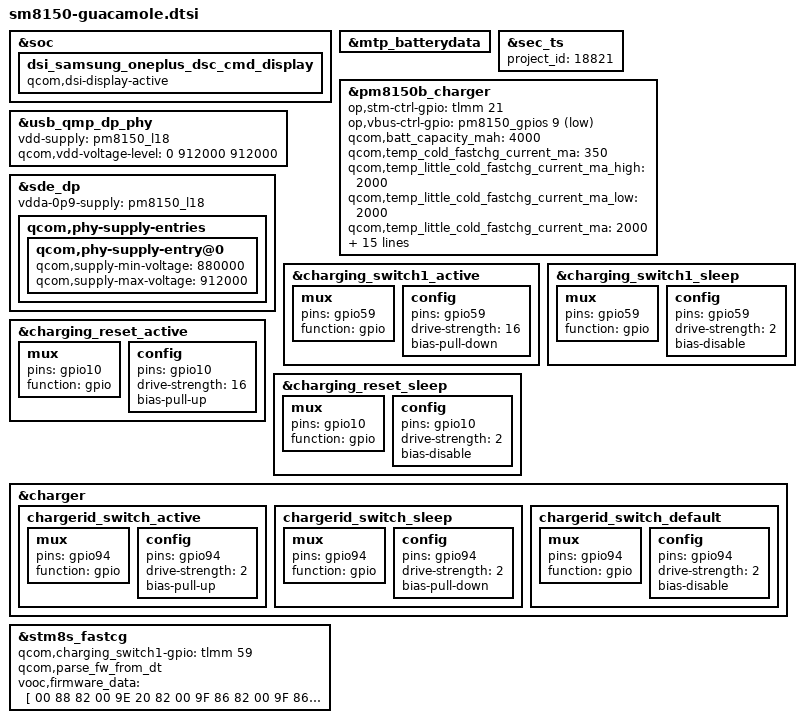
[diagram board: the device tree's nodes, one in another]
/*this is for different project dtsi*/
#include "sm8150-guacamole-common.dtsi"
#include "sm8150-camera-sensor-guacamole.dtsi"

&soc {
	dsi_samsung_oneplus_dsc_cmd_display {
		qcom,dsi-display-active;
	};
};

&mtp_batterydata {
	#include "OP-fg-batterydata-4000mah.dtsi"
};

&sec_ts {
	project_id = <18821>;
};

&pm8150b_charger {
	op,stm-ctrl-gpio = <&tlmm 21 0x00>;
	op,vbus-ctrl-gpio = <&pm8150_gpios 9 GPIO_ACTIVE_LOW>;
};

&usb_qmp_dp_phy {
	vdd-supply = <&pm8150_l18>;
	qcom,vdd-voltage-level = <0 912000 912000>;
};

&sde_dp {
	vdda-0p9-supply = <&pm8150_l18>;
	qcom,phy-supply-entries {
		qcom,phy-supply-entry@0 {
			qcom,supply-min-voltage = <880000>;
			qcom,supply-max-voltage = <912000>;
		};
	};
};

&charging_switch1_active {
	mux {
		pins = "gpio59";
		function = "gpio";
	};

	config {
		pins = "gpio59";
		drive-strength = <16>;
		bias-pull-down;
	};
};

&charging_switch1_sleep {
	mux {
		pins = "gpio59";
		function = "gpio";
	};

	config {
		pins = "gpio59";
		drive-strength = <2>;
		bias-disable;
	};
};

&charging_reset_active {
	mux {
		pins = "gpio10";
		function = "gpio";
	};

	config {
		pins = "gpio10";
		drive-strength = <16>;
		bias-pull-up;
	};
};

&charging_reset_sleep {
	mux {
		pins = "gpio10";
		function = "gpio";
	};

	config {
		pins = "gpio10";
		drive-strength = <2>;
		bias-disable;
	};
};

&charger {
	chargerid_switch_active: chargerid_switch_active {
		mux {
			pins = "gpio94";
			function = "gpio";
		};

		config {
			pins = "gpio94";
			drive-strength = <2>;
			bias-pull-up;
		};
	};

	chargerid_switch_sleep: chargerid_switch_sleep {
		mux {
			pins = "gpio94";
			function = "gpio";
		};

		config {
			pins = "gpio94";
			drive-strength = <2>;
			bias-pull-down;
		};
	};

	chargerid_switch_default: chargerid_switch_default {
		mux {
			pins = "gpio94";
			function = "gpio";
		};

		config {
			pins = "gpio94";
			drive-strength = <2>;
			bias-disable; /* NO PULL */
		};
	};
};

&pm8150b_charger {
	qcom,batt_capacity_mah = <4000>;/*typical capacity*/
	qcom,temp_cold_fastchg_current_ma = <350>;
	qcom,temp_little_cold_fastchg_current_ma_high = <2000>;
	qcom,temp_little_cold_fastchg_current_ma_low = <2000>;
	qcom,temp_little_cold_fastchg_current_ma = <2000>;
	qcom,temp_warm_fastchg_current_ma = <1100>;
	qcom,cold_vfloat_sw_limit = <3700>;
	qcom,cool_vfloat_sw_limit = <4270>;
	/delete-property/ qcom,support_abnormal_adapter;
	qcom,chargerid_switch-gpio = <&tlmm 94 0x00>;
	pinctrl-names = "ship_active", "ship_sleep",
		            "ccdetect_active", "ccdetect_sleep",
		            "dischg_enable", "dischg_disable",
		            "gpio1_adc_default", "gpio12_adc_default",
		            "chargerid_switch_active", "chargerid_switch_sleep", "chargerid_switch_default";
	pinctrl-0 = <&ship_active>;
	pinctrl-1 = <&ship_sleep>;
	pinctrl-2 = <&ccdetect_active>;
	pinctrl-3 = <&ccdetect_sleep>;
	pinctrl-4 = <&dischg_enable>;
	pinctrl-5 = <&dischg_disable>;
	pinctrl-6 = <&gpio1_adc_default>;
	pinctrl-7 = <&gpio12_adc_default>;
	pinctrl-8 = <&chargerid_switch_active>;
	pinctrl-9 = <&chargerid_switch_sleep>;
	pinctrl-10 = <&chargerid_switch_default>;
};

&stm8s_fastcg {
	/delete-property/ qcom,abnormal_adapter_current;
	/delete-property/ qcom,charging_switch1_ctr1-gpio;
	qcom,charging_switch1-gpio = <&tlmm 59 0x00>;
	qcom,parse_fw_from_dt;
	vooc,firmware_data = [
		00 88 82 00 9E 20 82 00 9F 86 82 00 9F 86 82 00 9F 86 82 00 9F 86 82 00 9C A2 82 00 9F 86 82 00 9F 6D 
		20 88 82 00 9F 86 82 00 9F 86 82 00 9F 86 82 00 9F 86 82 00 9F 86 82 00 9F 86 82 00 9F 86 82 00 97 96 
		40 88 82 00 9F 86 82 00 9F 86 82 00 9F 86 82 00 9F 86 82 00 9F 86 82 00 9F 86 82 00 9F 86 82 00 9F 86 
		60 88 82 00 9F 86 82 00 9F 86 82 00 9F 86 82 00 9F 86 82 00 9F 86 82 00 9F 86 82 00 9F 86 82 00 9F 86 
		80 88 C6 00 78 A1 08 24 17 CD 9F 47 B7 00 C6 00 78 5F 97 B6 00 D7 00 57 C6 00 78 4C C7 00 78 81 C6 00 
		A0 88 78 A1 08 27 03 CC 89 A9 CD 9E 67 C6 00 57 A1 01 26 41 C6 00 58 26 3C C6 00 59 A1 01 26 35 C6 00 
		C0 88 5B 48 48 88 C6 00 5A 48 48 48 B7 01 84 BA 01 B7 00 C6 00 5C 48 BA 00 CA 00 5D C7 00 7A 35 09 00 
		E0 88 78 C6 00 43 26 03 CC 89 A9 C6 00 43 4A C7 00 43 CC 89 A9 C6 00 57 26 33 C6 00 58 A1 01 26 2C C6 
		00 89 00 59 A1 01 26 25 C6 00 5B 48 48 88 C6 00 5A 48 48 48 B7 01 84 BA 01 B7 00 C6 00 5C 48 BA 00 CA 
		20 89 00 5D C7 00 7A 35 09 00 78 20 7E C6 00 58 B7 00 A1 01 26 3C C6 00 59 26 37 C6 00 5A A1 01 26 30 
		40 89 C6 00 5C 48 48 88 C6 00 5B 48 48 48 B7 01 84 BA 01 B7 00 C6 00 5D 48 BA 00 CA 00 5E C7 00 7A 35 
		60 89 09 00 78 C6 00 43 27 07 C6 00 43 4A C7 00 43 81 3D 00 26 32 C6 00 59 A1 01 26 2B C6 00 5A A1 01 
		80 89 26 24 C6 00 5C 48 48 88 C6 00 5B 48 48 48 B7 01 84 BA 01 B7 00 C6 00 5D 48 BA 00 CA 00 5E C7 00 
		A0 89 7A 35 09 00 78 81 CD 8F 7E C6 00 79 27 03 CC 8E B9 72 5F 00 49 72 5F 00 4A 72 5F 00 4B 72 5F 00 
		C0 89 4C 72 5F 00 4D 72 5F 00 4E 72 5F 00 4F C6 00 82 A1 02 26 10 C6 00 7A 4E A4 F0 C7 00 83 35 01 00 
		E0 89 4B CC 8E B9 C6 00 82 A1 01 26 10 C6 00 7A CA 00 83 C7 00 83 35 01 00 4B CC 8E B9 C6 00 84 A1 05 
		00 8A 26 2D C6 00 50 C7 00 49 C6 00 51 C7 00 4A C6 00 52 C7 00 4B C6 00 53 C7 00 4C C6 00 54 C7 00 4D 
		20 8A C6 00 55 C7 00 4E C6 00 56 C7 00 4F CC 8E B9 C6 00 84 A1 04 26 12 C6 00 7A 5F 97 CD 9A 62 CF 00 
		40 8A 61 35 01 00 4B CC 8E B9 C6 00 84 A1 03 26 1E C6 00 7A 5F 97 4F 02 90 CE 00 61 BF 00 51 02 BA 00 
		60 8A 01 51 90 CF 00 61 35 01 00 4B CC 8E B9 C6 00 84 A1 02 26 22 C6 00 7A 5F 97 CD 9A 6A 90 CE 00 61 
		80 8A BF 00 51 01 BA 01 01 BA 00 01 51 90 CF 00 61 35 01 00 4B CC 8E B9 C6 00 84 A1 01 26 2D C6 00 7A 
		A0 8A 90 5F 90 97 CE 00 61 90 BF 00 01 BA 01 02 CF 00 61 CD 9F 1C 35 01 00 4B CE 00 3A C3 00 61 27 03 
		C0 8A CC 8E B9 35 01 00 87 CC 8E B9 C6 00 85 27 5D C6 00 85 90 5F 90 97 AE 00 07 BF 00 93 CD 9A 10 1C 
		E0 8A 00 10 90 93 72 A9 FF F9 90 F6 C7 00 49 90 93 72 A9 FF FA 90 F6 C7 00 4A 90 93 72 A9 FF FB 90 F6 
		00 8B C7 00 4B 90 93 72 A9 FF FC 90 F6 C7 00 4C 90 93 72 A9 FF FD 90 F6 C7 00 4D 90 93 72 A9 FF FE 90 
		20 8B F6 C7 00 4E 5A F6 C7 00 4F CC 8E B9 C6 00 7A A1 09 26 11 72 5F 00 82 72 5F 00 84 4F CD 9E 89 35 
		40 8B 01 00 77 81 72 5F 00 82 72 5F 00 84 C6 00 7A 27 2B 4A 27 2B 4A 26 03 CC 8D 55 4A 26 03 CC 8D 9B 
		60 8B 4A 26 03 CC 8E 32 4A 26 03 CC 8E 7B A0 07 26 03 CC 8E 89 4A 26 03 CC 8E A9 CC 8E B9 CC 8F 7E C6 
		80 8B 00 43 27 03 CC 8C AA C6 00 45 A1 01 27 03 CD 8F 7E C6 00 76 C7 00 49 C6 00 98 27 24 C6 00 9C 26 
		A0 8B 1F 35 01 00 4A 35 01 00 4B 35 01 00 4C 72 5F 00 4D 35 01 00 4E 72 5F 00 4F 35 01 00 9C CC 8E B9 
		C0 8B CE 00 5F A3 0D 40 2E 03 CC 8C 98 CE 00 5F 1C F2 C0 90 AE 00 10 CD 9A 2E A3 00 3E 2F 03 AE 00 3D 
		E0 8B C6 00 97 27 13 C6 00 9D 26 0E A3 00 3A 2E 09 AE 00 3A 35 01 00 9D 20 16 C6 00 96 27 11 C6 00 9E 
		00 8C 26 0C A3 00 39 2E 07 AE 00 39 35 01 00 9E 9F CD 9F 16 A4 01 C7 00 4A 9F CD 9F 17 A4 01 C7 00 4B 
		20 8C 9F 47 47 47 A4 01 C7 00 4C 9F 47 47 A4 01 C7 00 4D 9F 47 A4 01 C7 00 4E 9F A4 01 C7 00 4F CD 9C 
		40 8C 0B A1 00 26 08 C6 00 8C 26 03 CC 8E B9 4F CD 9E 89 35 01 00 8C C6 00 95 26 1F 35 01 00 4A 35 01 
		60 8C 00 4B 35 01 00 4C 35 01 00 4D 35 01 00 4E 72 5F 00 4F 35 01 00 95 CC 8E B9 72 5F 00 4A 72 5F 00 
		80 8C 4B 72 5F 00 4C 35 01 00 4D 72 5F 00 4E 35 01 00 4F 72 5F 00 95 CC 8E B9 CE 00 5F A3 0B B8 2F 03 
		A0 8C CC 8E B9 72 5F 00 49 CC 8E B9 C6 00 8C 27 27 C6 00 95 26 17 35 01 00 49 35 01 00 4A 35 01 00 4E 
		C0 8C 35 01 00 4F 35 01 00 95 CC 8E B9 35 01 00 4C 72 5F 00 95 CC 8E B9 C6 00 8F 27 26 35 01 00 49 35 
		E0 8C 01 00 4A 35 01 00 4B 35 01 00 4C 35 01 00 4D 35 01 00 4E 35 01 00 4F C6 00 8F 4A C7 00 8F CC 8E 
		00 8D B9 CE 00 5F A3 0D 4C 2E 03 5F 20 0D CE 00 5F 1C F2 B4 90 AE 00 0A CD 9A 2E 9F CD 9F 15 A4 01 C7 
		20 8D 00 49 9F CD 9F 16 A4 01 C7 00 4A 9F CD 9F 17 A4 01 C7 00 4B 9F 47 47 47 A4 01 C7 00 4C 9F 47 47 
		40 8D A4 01 C7 00 4D 9F 47 A4 01 C7 00 4E 9F A4 01 C7 00 4F CC 8E B9 C6 00 43 26 0E C6 00 45 A1 02 27 
		60 8D 03 CD 8F 7E 35 01 00 49 35 03 00 00 A6 04 CD 98 F9 C7 00 9B C6 00 9B A1 02 26 07 35 01 00 4A CC 
		80 8D 8E B9 C6 00 9B A1 01 26 0B 35 01 00 4A 35 01 00 4B CC 8E B9 35 01 00 4B CC 8E B9 C6 00 43 26 4F 
		A0 8D C6 00 45 A1 03 27 03 CD 8F 7E C6 00 98 27 13 72 5F 00 4C 72 5F 00 4D 72 5F 00 4E 72 5F 00 4F CC 
		C0 8D 8E B9 C6 00 99 A1 01 26 13 72 5F 00 4C 72 5F 00 4D 35 01 00 4E 72 5F 00 4F CC 8E B9 72 5F 00 4C 
		E0 8D 72 5F 00 4D 35 01 00 4E 35 01 00 4F CC 8E B9 C6 00 92 CD 9F 10 A4 01 C7 00 4A C6 00 92 4E A4 0F 
		00 8E A4 01 C7 00 4B C6 00 92 44 44 44 A4 01 C7 00 4C C6 00 92 44 44 A4 01 C7 00 4D C6 00 92 44 A4 01 
		20 8E C7 00 4E C6 00 92 A4 01 C7 00 4F 72 5F 00 8F CC 8E B9 C6 00 44 27 11 C6 00 44 4A C7 00 44 35 01 
		40 8E 00 4C 35 01 00 4D 20 71 C6 00 43 27 08 C6 00 76 C7 00 49 20 E9 C6 00 45 A1 04 27 03 CD 8F 7E 35 
		60 8E 01 00 46 72 5F 00 47 35 01 00 48 C6 00 76 C7 00 49 35 01 00 4C 35 01 00 4D 20 3E 35 03 00 82 35 
		80 8E 01 00 4A 35 01 00 4C 20 30 C6 00 40 27 2B C6 00 89 27 26 C6 00 40 4A C7 00 40 35 06 00 84 CD 9F 
		A0 8E 67 C7 00 8B CD 98 50 20 10 35 07 00 85 35 08 00 86 35 01 00 4B 35 01 00 4C C6 00 79 5F 97 D6 00 
		C0 8E 46 CD 9E DB C6 00 79 4C C7 00 79 C6 00 79 A1 0A 24 03 CC 8F 7D CD 9B F5 CD 9E CE 72 5F 00 79 72 
		E0 8E 5F 00 78 72 5F 00 7B 72 5F 00 74 C6 00 82 27 08 C6 00 82 4A C7 00 82 81 C6 00 84 27 08 C6 00 84 
		00 8F 4A C7 00 84 81 C6 00 85 27 0F C6 00 85 4A C7 00 85 C6 00 86 4A C7 00 86 81 C6 00 7A 4A 27 4B 4A 
		20 8F 27 08 4A 27 45 4A 27 23 20 4A C6 00 9B A1 01 26 4C C6 00 88 A1 01 26 05 A6 01 CD 9E 89 72 5F 00 
		40 8F 9B C6 00 43 26 37 35 03 00 45 81 C6 00 43 26 0F C6 00 49 27 06 35 02 00 45 20 04 35 04 00 45 35 
		60 8F 01 00 89 CD 9F 67 C7 00 8A 81 C6 00 43 26 0E 35 01 00 45 81 C6 00 43 26 04 35 04 00 45 81 C6 00 
		80 8F 9A A1 02 27 0F C6 00 9A A1 01 26 05 35 02 00 9A 81 CD 9F 02 81 CD 99 B8 CD 99 BD 52 04 4F 6B 03 
		A0 8F 6B 02 6B 01 3F 0B 3F 0C 3F 0D 3F 0E 6B 04 3F 0F 3F 0A AE 0E 10 CF 00 3C AE 01 E0 CF 00 3E 20 0F 
		C0 8F CD 9F 02 CD 9F 28 CD 9F 28 AE 17 70 CF 00 6B CD 9F 77 CE 00 6B 26 5C A6 58 CD 95 F8 B7 00 C6 00 
		E0 8F 8C 26 E0 B6 00 A1 03 26 0D 4F CD 9E 89 35 01 00 8C CD 9B D2 20 CD A1 02 26 19 C6 00 8F 26 2F C6 
		00 90 00 91 B7 01 35 3C 00 00 C6 00 93 CD 9B 90 C7 00 8F 20 1B A1 01 26 A9 C6 00 8F 26 12 C6 00 91 B7 
		20 90 01 35 14 00 00 C6 00 93 CD 9B 90 C7 00 8F CD 9B D2 20 90 CE 00 69 27 03 CC 90 F0 C6 00 7D CD 9B 
		40 90 09 BF 08 C6 00 8C 27 03 CC 90 E1 A3 F8 30 2E 12 7B 01 4C 6B 01 7B 01 A1 04 25 0A A6 54 CD 9D B0 
		60 90 20 03 4F 6B 01 BE 08 A3 1B 59 2F 10 B6 0D 4C B7 0D A1 08 25 09 A6 59 CD 9D B0 20 02 3F 0D BE 08 
		80 90 A3 00 01 2F 22 A3 01 F4 2F 0D A3 03 84 2E 18 CE 00 5F A3 11 4F 2F 10 B6 0E 4C B7 0E A1 06 25 09 
		A0 90 A6 5A CD 9D B0 20 02 3F 0E C6 00 42 A1 02 26 2E BE 08 A3 04 B0 2E 27 CE 00 5F A3 11 59 2F 05 A6 
		C0 90 5A CD 9D B0 CE 00 5F A3 11 53 2F 12 7B 02 4C 6B 02 7B 02 A1 06 25 0A A6 5A CD 9D B0 20 03 4F 6B 
		E0 90 02 CD 9F 28 CD 9F 28 AE 03 E8 CF 00 69 CC 8F CF CE 00 67 26 36 C6 00 43 26 31 C6 00 7E CD 9B 09 
		00 91 A3 00 60 2F 15 C6 00 8C 26 10 B6 0B 4C B7 0B A1 04 25 09 A6 5A CD 9D B0 20 02 3F 0B CD 9F 28 CD 
		20 91 9F 28 AE 07 D0 CF 00 67 CC 8F CF CE 00 65 26 77 C6 00 7C CD 9B 09 CF 00 5F C6 00 8C 26 5A CE 00 
		40 91 3E 27 08 CE 00 5F A3 10 9B 2F 0B C6 00 93 A1 33 25 04 35 32 00 93 C6 00 8F 26 13 C6 00 91 B7 01 
		60 91 C6 00 90 B7 00 C6 00 93 CD 9B 90 C7 00 8F CE 00 5F A3 11 59 2F 05 A6 5A CD 9D B0 CE 00 5F A3 11 
		80 91 53 2F 12 7B 03 4C 6B 03 7B 03 A1 06 25 0A A6 5A CD 9D B0 20 03 4F 6B 03 CD 9F 28 CD 9F 28 AE 01 
		A0 91 F4 CF 00 65 CC 8F CF CE 00 6F 27 03 CC 93 22 C6 00 7F CD 9B 09 BF 08 A3 01 5F 2F 05 1C FF E2 BF 
		C0 91 08 C6 00 8C 27 03 CC 93 13 BE 08 A3 01 B3 2F 13 B6 0A 4C B7 0A A1 03 25 28 35 03 00 0A 35 01 00 
		E0 91 97 20 1E A3 01 A5 2F 15 3F 0A B6 0F 4C B7 0F A1 03 25 0E 35 03 00 0F 35 01 00 96 20 04 3F 0F 3F 
		00 92 0A 1C FF 8D A3 01 46 25 14 B6 0C 4C B7 0C A1 03 24 03 CC 93 13 A6 5C CD 9D B0 CC 93 13 3F 0C C6 
		20 92 00 8F 27 03 CC 92 F4 C6 00 41 4A 27 0F 4A 27 2F 4A 27 68 4A 26 03 CC 92 D7 CC 92 F4 BE 08 A3 01 
		40 92 9B 2E 03 CC 92 F4 35 24 00 01 C6 00 90 B7 00 C6 00 93 CD 9B 90 C7 00 8F 35 02 00 41 CC 92 F4 BE 
		60 92 08 A3 01 A5 2F 18 35 14 00 01 C6 00 90 B7 00 C6 00 93 CD 9B 90 C7 00 8F 35 03 00 41 20 76 A3 01 
		80 92 86 2E 71 35 24 00 01 C6 00 90 B7 00 C6 00 93 CD 9B 90 C7 00 8F 35 01 00 41 20 59 BE 08 A3 01 B4 
		A0 92 2F 18 35 14 00 01 C6 00 90 B7 00 C6 00 93 CD 9B 90 C7 00 8F 35 04 00 41 20 3A A3 01 90 2E 35 35 
		C0 92 14 00 01 C6 00 90 B7 00 C6 00 93 CD 9B 90 C7 00 8F 35 02 00 41 20 1D BE 08 A3 01 9F 2E 16 35 14 
		E0 92 00 01 C6 00 90 B7 00 C6 00 93 CD 9B 90 C7 00 8F 35 03 00 41 C6 00 42 A1 01 26 0D BE 08 A3 01 5F 
		00 93 2F 11 35 02 00 42 20 0B BE 08 A3 01 59 2E 04 35 01 00 42 CD 9F 28 CD 9F 28 AE 01 F4 CF 00 6F CC 
		20 93 8F CF CE 00 71 26 33 C6 00 8C 26 18 CD 9C 0B A1 00 27 08 4F CD 9E 89 35 01 00 8C AE 03 20 CF 00 
		40 93 71 CC 8F CF 0D 04 26 09 A6 5D CD 95 F8 A6 01 6B 04 AE 27 10 CF 00 71 CC 8F CF CE 00 6D 27 03 CC 
		60 93 8F CF CE 00 3C 26 0A C6 00 8C 26 05 A6 5A CD 9D B0 C6 00 74 26 07 C6 00 9A A1 02 25 11 C6 00 77 
		80 93 27 07 A6 59 CD 9D B0 20 05 A6 54 CD 9D B0 C6 00 77 27 05 A6 59 CD 9D B0 AE 00 14 CF 00 6D CC 8F 
		A0 93 CF CD 9F 72 CD 9A 6F CD 96 CE CD 9C CD CD 9A C4 CD 9D F7 4F CD 9D 73 4F CD 9C 72 4F CD 9C 42 A6 
		C0 93 01 CD 9D 73 CD 9F 5B CD 9F 61 A1 00 27 F6 CD 9D E2 CD 9F 77 20 03 CD 9F 28 CD 9F 77 C6 00 74 27 
		E0 93 03 CD 9F 02 C6 00 87 A1 01 26 07 C6 00 86 A1 01 27 05 C6 00 43 26 DF 35 01 00 88 CD 9C DF A6 52 
		00 94 CD 95 F8 35 01 00 9A 4D 26 03 CD 9F 02 CD 9F 77 A6 5E CD 95 F8 A1 02 27 03 CD 9F 02 CD 9F 77 CD 
		20 94 9F 28 CD 9F 77 C6 00 83 CD 95 F8 A1 02 27 03 CD 9F 02 CD 9F 77 C6 00 80 26 12 35 08 00 7C 35 14 
		40 94 00 7D 35 2C 00 7E 35 06 00 7F 20 17 C6 00 80 A1 01 26 10 35 04 00 7C 35 10 00 7D 35 1C 00 7E 35 
		60 94 02 00 7F 35 01 00 81 CD 9F 77 C6 00 7C CD 9B 09 CF 00 5F CD 9F 28 C6 00 7F CD 9B 09 A3 00 A0 2E 
		80 94 0C 35 24 00 92 35 24 00 93 35 01 00 99 CD 9F 28 C6 00 7E CD 9B 09 9F A1 4C 25 10 35 14 00 90 35 
		A0 94 14 00 91 35 14 00 92 35 14 00 93 25 04 35 01 00 98 35 01 00 76 20 14 CD 9F 77 C6 00 74 26 07 C6 
		C0 94 00 9A A1 02 25 05 A6 54 CD 9D B0 CD 9F 33 A1 01 27 E5 CD 8F 95 5F 81 CD 99 B8 B7 0A 45 00 0B BF 
		E0 94 08 CD 9F 77 72 03 52 19 0B 72 12 52 11 72 02 52 11 FB 20 F0 CD 9F 77 72 14 52 11 72 10 52 11 CD 
		00 95 9F 77 72 01 52 17 FB CD 9F 77 35 AA 52 16 CD 9F 77 72 03 52 17 FB CD 9F 77 9D 9D C6 52 19 CD 9F 
		20 95 77 72 0F 52 17 FB B6 0A C7 52 16 C6 52 17 A4 84 A1 84 26 F7 9D 9D 9D 9D 72 10 52 11 72 01 52 17 
		40 95 FB CD 9F 77 35 AB 52 16 72 03 52 17 FB CD 9F 77 B6 0B A1 03 25 4C C6 52 19 20 15 72 05 52 17 FB 
		60 95 C6 52 16 92 C7 08 BE 08 5C BF 08 B6 0B 4A B7 0B B6 0B A1 04 24 E5 72 05 52 17 FB 72 15 52 11 9B 
		80 95 C6 52 16 92 C7 08 BE 08 5C 72 12 52 11 C6 52 16 F7 5C BF 08 9A 72 0D 52 17 FB C6 52 16 92 C7 08 
		A0 95 20 47 A1 02 26 2B 72 16 52 11 9B C6 52 19 72 15 52 11 9A 72 05 52 17 FB 9B 72 12 52 11 C6 52 16 
		C0 95 92 C7 08 BE 08 5C BF 08 9A C6 52 16 92 C7 08 20 18 72 15 52 11 9B C6 52 19 72 12 52 11 9A 72 0D 
		E0 95 52 17 FB C6 52 16 92 C7 08 72 02 52 11 FB 72 17 52 11 CD 9F 77 CC 9A 08 CD 99 87 3B 00 0A B7 08 
		00 96 3F 0A CD 9F 77 72 5F 00 75 CD 9E 33 3F 09 20 34 C6 00 74 27 09 B6 08 A1 58 26 03 CD 9E CE CD 9F 
		20 96 77 C6 00 75 27 FB CD 9F 77 A6 06 B0 09 5F 41 B6 08 41 CD 9A 5A 9F A4 01 CD 9E B4 72 5F 00 75 B6 
		40 96 09 4C B7 09 B6 09 A1 07 25 C6 CD 9F 77 3F 09 20 16 A6 01 B0 09 5F 41 B6 00 41 CD 9A 52 9F BA 0A 
		60 96 B7 0A B6 09 4C B7 09 B6 09 A1 03 24 3E C6 00 74 27 09 B6 08 A1 58 26 03 CD 9E CE CD 9F 77 C6 00 
		80 96 75 27 FB CD 9F 77 3D 09 26 06 CD 9E A7 CD 9F 51 72 5F 00 75 CD 9F 3D B7 00 B6 09 A1 02 26 B2 C6 
		A0 96 00 81 26 BE B6 00 C7 00 80 20 B7 CD 9F 77 C6 00 75 27 FB CD 9F 77 CD 9E 56 72 5F 00 75 CD 9F 28 
		C0 96 CD 9F 28 CD 9F 77 B6 0A 32 00 0A CC 9A 0C 5F CF 00 5F 72 5F 00 74 72 5F 00 75 72 5F 00 76 72 5F 
		E0 96 00 77 72 5F 00 78 72 5F 00 46 35 01 00 47 35 01 00 48 72 5F 00 79 72 5F 00 7A 72 5F 00 7B 72 5F 
		00 97 00 7C 72 5F 00 7D 72 5F 00 7E 72 5F 00 7F 72 5F 00 80 72 5F 00 81 72 5F 00 96 72 5F 00 97 72 5F 
		20 97 00 82 72 5F 00 83 35 03 00 40 72 5F 00 84 72 5F 00 85 72 5F 00 86 CF 00 61 5A CF 00 3A 72 5F 00 
		40 97 87 72 5F 00 88 72 5F 00 89 72 5F 00 8A 72 5F 00 8B 72 5F 00 8C 72 5F 00 8D 72 5F 00 8E 72 5F 00 
		60 97 8F 35 3C 00 90 35 3C 00 91 35 3C 00 92 35 3C 00 93 35 01 00 41 35 01 00 42 72 5F 00 94 72 5F 00 
		80 97 95 35 03 00 43 35 03 00 44 72 5F 00 9A 35 04 00 45 72 5F 00 99 81 8A 84 A4 BF 88 86 CD 99 AE CD 
		A0 97 99 B3 72 11 53 04 CE 00 63 27 09 CE 00 63 5A CF 00 63 20 1E AE 03 E8 CF 00 63 CE 00 3C 27 07 CE 
		C0 97 00 3C 5A CF 00 3C CE 00 3E 27 07 CE 00 3E 5A CF 00 3E CE 00 65 27 07 CE 00 65 5A CF 00 65 CE 00 
		E0 97 67 27 07 CE 00 67 5A CF 00 67 CE 00 69 27 07 CE 00 69 5A CF 00 69 CE 00 6B 27 07 CE 00 6B 5A CF 
		00 98 00 6B CE 00 6D 27 07 CE 00 6D 5A CF 00 6D CE 00 6F 27 07 CE 00 6F 5A CF 00 6F CE 00 71 27 07 CE 
		20 98 00 71 5A CF 00 71 C6 00 8E 4C C7 00 8E C6 00 8E A1 C9 25 15 72 5F 00 8E C6 00 7B 27 08 4F CD 9E 
		40 98 89 35 01 00 74 35 01 00 7B CD 99 EA CD 99 DF 80 C6 00 8B 5F 97 58 BF 00 C6 00 8A 5F 97 4F 02 58 
		60 98 01 BA 01 01 BA 00 01 CF 00 3A C6 00 8A CD 9F 0F A4 01 C7 00 4B C6 00 8A CD 9F 10 A4 01 C7 00 51 
		80 98 C6 00 8A 4E A4 0F A4 01 C7 00 4E C6 00 8A 44 44 44 A4 01 C7 00 56 C6 00 8A 44 44 A4 01 C7 00 54 
		A0 98 C6 00 8A 44 A4 01 C7 00 53 C6 00 8A A4 01 C7 00 4D C6 00 8B CD 9F 0F A4 01 C7 00 49 C6 00 8B CD 
		C0 98 9F 10 A4 01 C7 00 52 C6 00 8B 4E A4 0F A4 01 C7 00 4A C6 00 8B 44 44 44 A4 01 C7 00 50 C6 00 8B 
		E0 98 44 44 A4 01 C7 00 4F C6 00 8B 44 A4 01 C7 00 55 C6 00 8B A4 01 C7 00 4C 81 CD 99 87 3B 00 0A 45 
		00 99 00 0A CD 9B 4D BF 08 B6 0A CD 9B 4D BF 00 BE 08 72 B0 00 00 90 CE 00 5F 90 A3 0E 74 2E 08 35 12 
		20 99 00 00 A6 25 20 3C 90 CE 00 5F 90 A3 0E D8 2E 08 35 12 00 00 A6 24 20 2A 90 CE 00 5F 90 A3 0F A0 
		40 99 2E 08 35 11 00 00 A6 22 20 18 90 CE 00 5F 90 A3 10 04 2E 08 35 10 00 00 A6 21 20 06 35 10 00 00 
		60 99 A6 20 90 5F 61 B6 00 61 90 BF 00 B3 00 2E 03 4F 20 0F 90 97 BF 00 90 B3 00 2E 04 A6 02 20 02 A6 
		80 99 01 32 00 0A CC 9A 0C 88 A6 08 20 00 88 7B 02 88 7B 02 89 1E 06 1F 04 5F 97 FE 1F 06 85 84 81 89 
		A0 99 1E 05 BF 08 20 00 1E 03 1F 05 85 5B 02 81 88 A6 00 20 0F 88 A6 04 20 0A 88 A6 08 20 05 88 A6 0C 
		C0 99 20 00 88 89 7B 04 88 7B 04 89 1E 08 1F 04 5F 97 1F 08 FE 1F 06 1E 08 5C 5C FE 1F 08 85 84 81 89 
		E0 99 1E 05 BF 00 1E 07 BF 02 20 16 89 1E 05 BF 04 1E 07 BF 06 20 0B 89 1E 05 BF 08 1E 07 BF 0A 20 00 
		00 9A 1E 03 1F 07 85 5B 04 81 CD 99 F5 81 CD 99 9F 81 88 89 5E B6 01 42 89 1E 03 B6 00 42 72 FB 01 4F 
		20 9A 02 89 1E 05 B6 01 42 72 FB 01 5B 06 84 81 5D 2B 06 90 5D 2B 0A 65 81 50 90 5D 2B 07 65 50 81 90 
		40 9A 50 20 F9 90 50 20 EE CD 9E 99 02 B4 00 02 B4 01 02 81 4D 27 04 58 4A 26 FC 81 4D 27 04 57 4A 26 
		60 9A FC 81 58 58 58 58 58 58 58 58 58 58 58 58 81 3B 00 08 3F 08 35 01 00 8D 4F CD 9D 73 CD 9E 78 20 
		80 9A 2B 4F CD 9E F5 A6 01 CD 9B DE A6 01 CD 9E F5 A6 01 CD 9B DE 4F CD 9E F5 A6 02 CD 9B DE A6 01 CD 
		A0 9A 9E F5 A6 03 CD 9B DE B6 08 4C B7 08 B6 08 A1 0F 25 CF A6 01 CD 9C 72 A6 C8 CD 9B DE 72 5F 00 8D 
		C0 9A 32 00 08 81 C6 50 05 AA 30 C7 50 05 C6 50 07 AA 30 C7 50 07 C6 50 08 A4 CF C7 50 08 C6 50 09 AA 
		E0 9A 30 C7 50 09 35 01 52 12 35 50 52 1B 72 5F 52 1C 35 09 52 1D 35 A2 52 13 72 1C 52 14 35 01 52 1A 
		00 9B 72 14 52 11 72 10 52 10 81 3B 00 08 52 02 B7 08 96 5C 35 02 00 00 CD 94 D7 7B 02 5F 97 4F 02 7B 
		20 9B 01 90 5F 90 97 90 BF 00 01 BA 01 02 C6 00 80 26 06 B6 08 A1 06 27 0D C6 00 80 A1 01 26 09 B6 08 
		40 9B A1 02 26 03 1C F5 55 5B 02 32 00 08 81 9D 3B 00 08 B7 08 CD 9D 54 B6 08 CA 54 00 C7 54 00 A6 32 
		60 9B B7 00 4A 3D 00 26 F9 72 10 54 01 72 0F 54 00 FB 72 1F 54 00 C6 54 05 B7 00 C6 54 04 5F 97 4F 02 
		80 9B 90 5F B6 00 61 BF 00 93 02 BA 00 01 32 00 08 81 B7 02 C6 00 92 B7 03 B6 02 C1 00 93 24 03 C7 00 
		A0 9B 93 B6 00 C7 00 90 B6 01 C7 00 91 B6 00 B1 01 24 03 45 00 01 B6 01 C1 00 93 24 05 C7 00 92 20 06 
		C0 9B C6 00 93 C7 00 92 C6 00 92 B1 03 27 03 A6 05 81 4F 81 CD 9C 00 CD 9C 00 CD 9C 00 CC 9C 00 3B 00 
		E0 9B 08 B7 08 20 08 CD 9C 00 B6 08 4A B7 08 3D 08 26 F4 32 00 08 81 AE 01 4D 90 93 5A 90 5D 26 F9 81 
		00 9C AE 00 F3 90 93 5A 90 5D 26 F9 81 A6 02 CD 9B 4D A3 01 51 25 14 A6 05 CD 9B 4D A3 00 A8 25 0A A6 
		20 9C 06 CD 9B 4D A3 00 A8 24 09 C6 00 94 4C C7 00 94 20 04 72 5F 00 94 C6 00 94 A1 0A 25 03 A6 01 81 
		40 9C 4F 81 3B 00 08 B7 08 27 04 4F CD 9D 73 72 1D 50 0C 72 1D 50 0D 72 1C 50 0E C6 50 A0 A4 CF C7 50 
		60 9C A0 72 18 50 A0 3D 08 27 05 A6 01 CD 9D 73 32 00 08 81 3B 00 08 B7 08 27 04 4F CD 9D 73 72 15 50 
		80 9C 02 72 15 50 03 72 14 50 04 C6 50 A0 A4 FC C7 50 A0 72 10 50 A0 3D 08 27 05 A6 01 CD 9D 73 32 00 
		A0 9C 08 81 8A 84 A4 BF 88 86 CD 99 AE CD 99 B3 C6 00 8D 26 13 C6 00 73 26 0B CD 9F 7C 72 5F 00 8E 35 
		C0 9C 01 00 73 CD 88 80 CD 99 EA CD 99 DF 80 CD 9E 45 CD 9E A7 CD 9E C1 CD 9E CE CD 9E E8 CC 9C E4 72 
		E0 9C 18 50 0F 81 72 18 50 11 72 18 50 12 72 19 50 13 72 19 50 0F 81 89 FE 90 93 85 5C 5C 90 5D 27 1C 
		00 9D 89 FE BF 00 85 5C 5C 89 FE BF 02 85 5C 5C 51 5A 92 D6 00 92 D7 02 5A 2A F7 51 20 D9 81 72 5F 52 
		20 9D 62 35 10 52 63 72 5F 52 69 35 08 52 6A 35 68 52 5A 35 01 52 5D C6 52 6D AA C8 C7 52 6D 72 10 52 
		40 9D 50 81 9D 92 00 5A 00 46 00 00 9C F5 00 36 9F 93 00 10 00 00 72 5F 54 00 C6 54 01 A4 8F C7 54 01 
		60 9D C6 54 01 C7 54 01 72 13 54 01 72 16 54 02 72 10 54 01 81 B7 00 27 0C C6 00 9F 26 07 9A B6 00 C7 
		80 9D 00 9F 81 3D 00 26 0A C6 00 9F 27 05 9B 72 5F 00 9F 81 89 FE 90 93 85 5C 5C 90 5D 27 12 89 FE BF 
		A0 9D 00 85 5C 5C 51 5A 92 6F 00 5A 2A FA 51 20 E3 81 3B 00 08 B7 08 CD 9F 77 4F CD 9E 89 CD 9E CE B6 
		C0 9D 08 CD 95 F8 CD 9F 02 32 00 08 81 90 AE 9D 42 20 0A 93 1C 00 02 90 FE 90 FD 90 93 90 A3 9D 54 26 
		E0 9D F0 81 35 CC 50 E0 35 55 50 E0 35 06 50 E1 35 FF 50 E2 35 AA 50 E0 81 72 5F 53 0E 35 3E 53 0F 35 
		00 9E 80 53 10 72 1E 53 00 35 01 53 03 81 CD 99 87 52 02 BF 08 BE 08 1F 01 96 5C A6 01 CD 9F 92 20 F3 
		20 9E AE 03 FF 94 CD 9F 89 5D 27 03 CD 9D CB CD 93 A1 CC 9F 8C CD 9E 56 CD 9F 51 4F CD 9E B4 CD 9F 28 
		40 9E A6 01 CC 9E B4 72 16 50 02 72 16 50 03 72 17 50 04 72 16 50 00 81 72 1A 50 0C 72 1A 50 0D 72 1B 
		60 9E 50 0E 72 1B 50 0A 81 72 1E 50 0C 72 1E 50 0D 72 1F 50 0E 72 1F 50 0A 81 72 14 50 02 72 14 50 03 
		80 9E 72 15 50 04 72 15 50 00 81 4D 27 08 CD 9D 1D 72 17 50 00 81 72 16 50 00 81 89 1E 05 5C 5C 1F 05 
		A0 9E 5A 5A FE BF 00 85 81 72 1B 50 0C 72 1B 50 0D 72 1B 50 0E 81 4D 27 05 72 1A 50 0A 81 72 1B 50 0A 
		C0 9E 81 72 1D 50 0C 72 1D 50 0D 72 1D 50 0E 81 72 1F 50 0C 72 1F 50 0D 72 1F 50 0E 81 4D 27 05 72 1E 
		E0 9E 50 0A 81 72 1F 50 0A 81 72 15 50 02 72 15 50 03 72 15 50 04 81 4D 27 05 72 14 50 00 81 72 15 50 
		00 9F 00 81 35 7F 50 D2 35 80 50 D1 35 7F 50 D2 81 44 44 4E A4 0F 81 47 47 47 47 47 47 81 CE 00 61 CD 
		20 9F 9A 47 FE FE CF 00 61 81 AE 2C E6 90 93 5A 90 5D 26 F9 81 72 07 50 01 03 A6 01 81 4F 81 72 0B 50 
		40 9F 0B 03 A6 01 81 4F 81 72 0F 50 0B 03 A6 01 81 4F 81 A6 18 B7 00 4A 3D 00 26 F9 81 9D 9D 8E 9D 9D 
		60 9F 81 C6 53 00 A4 01 81 C6 53 0D A4 7F 81 35 01 00 75 80 35 02 50 C6 81 35 AA 50 E0 81 35 01 53 00 
		80 9F 81 89 85 CD 9E 0C CC 9F 8F 5F 5C 81 CC 9F 81 9D 20 FD 81 00 01 00 00 01 00 00 01 00 01 00 01 00 
		A0 9F 01 00 00 01 01 01 01 00 01 01 00 00 01 00 00 00 00 01 00 01 00 00 01 01 00 00 01 01 00 FF FF 0E 
		C0 9F 10 01 E0 03 01 01 03 03 04 FF FF FF FF FF FF FF FF FF FF FF FF FF FF FF FF FF FF FF FF FF FF FF 
		E0 9F FF FF FF FF FF FF FF FF FF FF FF FF FF FF FF FF FF FF FF FF FF FF FF FF FF FF FF FF 53 34 55 34 
	];
};
